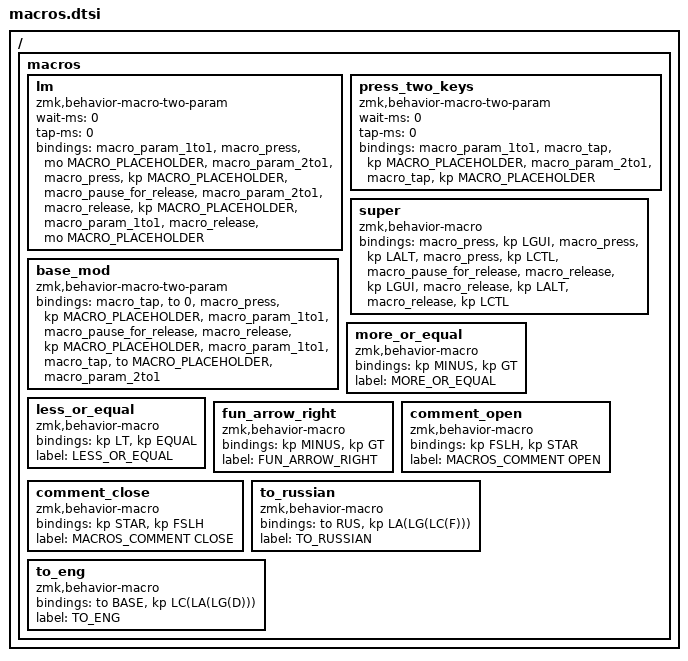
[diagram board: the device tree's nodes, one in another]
/ {
    macros {
        /**
         * Temporarily switches to a layer (`&mo`) while a modifier is held.
         * Analogous to QMK's `LM()`, using a parameterized macro.
         *
         * Params:
         *  1. Layer to switch to
         *  2. Modifier to press while layer is active
         *
         * Example:
         *  `&lm NUM_LAYER LSHIFT`
         */
        lm: lm {
            compatible = "zmk,behavior-macro-two-param";
            wait-ms = <0>;
            tap-ms = <0>;
            #binding-cells = <2>;
            bindings =
                <&macro_param_1to1>,
                <&macro_press>,
                <&mo MACRO_PLACEHOLDER &macro_param_2to1>,
                <&macro_press>,
                <&kp MACRO_PLACEHOLDER>,
                <&macro_pause_for_release>,
                <&macro_param_2to1>,
                <&macro_release>,
                <&kp MACRO_PLACEHOLDER &macro_param_1to1>,
                <&macro_release>,
                <&mo MACRO_PLACEHOLDER>;
        };

        press_two_keys: press_two_keys {
            compatible = "zmk,behavior-macro-two-param";
            wait-ms = <0>;
            tap-ms = <0>;
            #binding-cells = <2>;
            bindings =
                <&macro_param_1to1>,
                <&macro_tap>,
                <&kp MACRO_PLACEHOLDER &macro_param_2to1>,
                <&macro_tap>,
                <&kp MACRO_PLACEHOLDER>;
        };

        super: super {
            compatible = "zmk,behavior-macro";
            #binding-cells = <0>;
            bindings
                = <&macro_press &kp LGUI>
                , <&macro_press &kp LALT>
                , <&macro_press &kp LCTL>
                , <&macro_pause_for_release>
                , <&macro_release &kp LGUI>
                , <&macro_release &kp LALT>
                , <&macro_release &kp LCTL>
                ;
        };

        /**
         * go to first layer with pressed modifier, then go to another layer
         * use &base_mod MODIFIER LAYER-TO-GO-BACK
         */
        base_mod: base_mod {
            compatible = "zmk,behavior-macro-two-param";
            #binding-cells = <2>;
            bindings
                = <&macro_tap &to 0>
                , <&macro_press &kp MACRO_PLACEHOLDER &macro_param_1to1>
                , <&macro_pause_for_release>
                , <&macro_release &kp MACRO_PLACEHOLDER &macro_param_1to1>
                , <&macro_tap &to MACRO_PLACEHOLDER &macro_param_2to1>
                ;
        };

        more_or_equal: more_or_equal {
            compatible = "zmk,behavior-macro";
            #binding-cells = <0>;
            bindings = <&kp MINUS &kp GT>;
            label = "MORE_OR_EQUAL";
        };

        less_or_equal: less_or_equal {
            compatible = "zmk,behavior-macro";
            #binding-cells = <0>;
            bindings = <&kp LT &kp EQUAL>;
            label = "LESS_OR_EQUAL";
        };

        fun_arrow_right: fun_arrow_right {
            compatible = "zmk,behavior-macro";
            #binding-cells = <0>;
            bindings = <&kp MINUS &kp GT>;
            label = "FUN_ARROW_RIGHT";
        };

        comment_open: comment_open {
            compatible = "zmk,behavior-macro";
            #binding-cells = <0>;
            bindings = <&kp FSLH &kp STAR>;
            label = "MACROS_COMMENT OPEN";
        };

        comment_close: comment_close {
            compatible = "zmk,behavior-macro";
            #binding-cells = <0>;
            bindings = <&kp STAR &kp FSLH>;
            label = "MACROS_COMMENT CLOSE";
        };

        to_russian: to_russian {
            compatible = "zmk,behavior-macro";
            #binding-cells = <0>;
            bindings = <&to RUS &kp LA(LG(LC(F)))>;
            label = "TO_RUSSIAN";
        };

        to_eng: to_eng {
            compatible = "zmk,behavior-macro";
            #binding-cells = <0>;
            bindings = <&to BASE &kp LC(LA(LG(D)))>;
            label = "TO_ENG";
        };
    };
};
